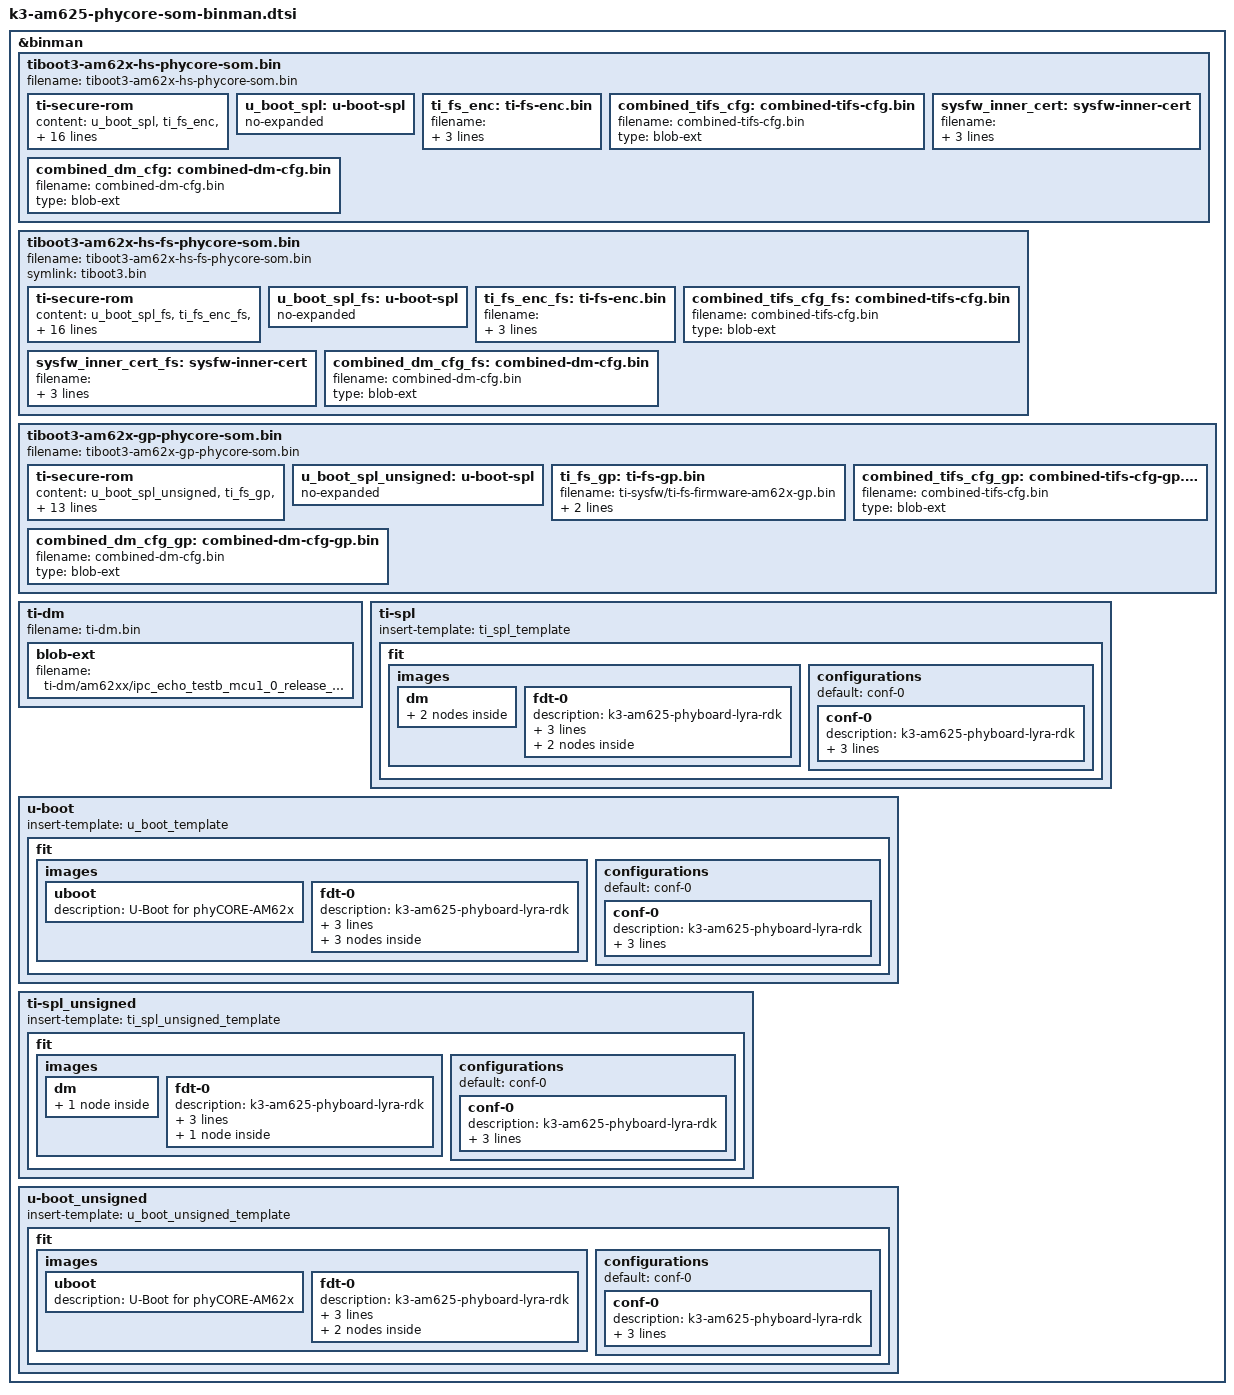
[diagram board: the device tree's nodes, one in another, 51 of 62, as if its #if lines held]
// SPDX-License-Identifier: GPL-2.0
/*
 * Based on k3-am625-sk-binman.dtsi
 *
 * Copyright (C) 2022 - 2023 PHYTEC Messtechnik GmbH
 * Author: Wadim Egorov <w.egorov@phytec.de>
 */

#include "k3-binman.dtsi"

#ifdef CONFIG_TARGET_PHYCORE_AM62X_R5
&binman {
	tiboot3-am62x-hs-phycore-som.bin {
		filename = "tiboot3-am62x-hs-phycore-som.bin";
		ti-secure-rom {
			content = <&u_boot_spl>, <&ti_fs_enc>, <&combined_tifs_cfg>,
				<&combined_dm_cfg>, <&sysfw_inner_cert>;
			combined;
			dm-data;
			sysfw-inner-cert;
			keyfile = "custMpk.pem";
			sw-rev = <1>;
			content-sbl = <&u_boot_spl>;
			content-sysfw = <&ti_fs_enc>;
			content-sysfw-data = <&combined_tifs_cfg>;
			content-sysfw-inner-cert = <&sysfw_inner_cert>;
			content-dm-data = <&combined_dm_cfg>;
			load = <0x43c00000>;
			load-sysfw = <0x40000>;
			load-sysfw-data = <0x67000>;
			load-dm-data = <0x43c3a800>;
		};
		u_boot_spl: u-boot-spl {
			no-expanded;
		};
		ti_fs_enc: ti-fs-enc.bin {
			filename = "ti-sysfw/ti-fs-firmware-am62x-hs-enc.bin";
			type = "blob-ext";
			optional;
		};
		combined_tifs_cfg: combined-tifs-cfg.bin {
			filename = "combined-tifs-cfg.bin";
			type = "blob-ext";
		};
		sysfw_inner_cert: sysfw-inner-cert {
			filename = "ti-sysfw/ti-fs-firmware-am62x-hs-cert.bin";
			type = "blob-ext";
			optional;
		};
		combined_dm_cfg: combined-dm-cfg.bin {
			filename = "combined-dm-cfg.bin";
			type = "blob-ext";
		};
	};
};

&binman {
	tiboot3-am62x-hs-fs-phycore-som.bin {
		filename = "tiboot3-am62x-hs-fs-phycore-som.bin";
		symlink = "tiboot3.bin";
		ti-secure-rom {
			content = <&u_boot_spl_fs>, <&ti_fs_enc_fs>, <&combined_tifs_cfg_fs>,
				<&combined_dm_cfg_fs>, <&sysfw_inner_cert_fs>;
			combined;
			dm-data;
			sysfw-inner-cert;
			keyfile = "custMpk.pem";
			sw-rev = <1>;
			content-sbl = <&u_boot_spl_fs>;
			content-sysfw = <&ti_fs_enc_fs>;
			content-sysfw-data = <&combined_tifs_cfg_fs>;
			content-sysfw-inner-cert = <&sysfw_inner_cert_fs>;
			content-dm-data = <&combined_dm_cfg_fs>;
			load = <0x43c00000>;
			load-sysfw = <0x40000>;
			load-sysfw-data = <0x67000>;
			load-dm-data = <0x43c3a800>;
		};
		u_boot_spl_fs: u-boot-spl {
			no-expanded;
		};
		ti_fs_enc_fs: ti-fs-enc.bin {
			filename = "ti-sysfw/ti-fs-firmware-am62x-hs-fs-enc.bin";
			type = "blob-ext";
			optional;
		};
		combined_tifs_cfg_fs: combined-tifs-cfg.bin {
			filename = "combined-tifs-cfg.bin";
			type = "blob-ext";
		};
		sysfw_inner_cert_fs: sysfw-inner-cert {
			filename = "ti-sysfw/ti-fs-firmware-am62x-hs-fs-cert.bin";
			type = "blob-ext";
			optional;
		};
		combined_dm_cfg_fs: combined-dm-cfg.bin {
			filename = "combined-dm-cfg.bin";
			type = "blob-ext";
		};
	};
};

&binman {
	tiboot3-am62x-gp-phycore-som.bin {
		filename = "tiboot3-am62x-gp-phycore-som.bin";
		ti-secure-rom {
			content = <&u_boot_spl_unsigned>, <&ti_fs_gp>,
				<&combined_tifs_cfg_gp>, <&combined_dm_cfg_gp>;
			combined;
			dm-data;
			content-sbl = <&u_boot_spl_unsigned>;
			load = <0x43c00000>;
			content-sysfw = <&ti_fs_gp>;
			load-sysfw = <0x40000>;
			content-sysfw-data = <&combined_tifs_cfg_gp>;
			load-sysfw-data = <0x67000>;
			content-dm-data = <&combined_dm_cfg_gp>;
			load-dm-data = <0x43c3a800>;
			sw-rev = <1>;
			keyfile = "ti-degenerate-key.pem";
		};
		u_boot_spl_unsigned: u-boot-spl {
			no-expanded;
		};
		ti_fs_gp: ti-fs-gp.bin {
			filename = "ti-sysfw/ti-fs-firmware-am62x-gp.bin";
			type = "blob-ext";
			optional;
		};
		combined_tifs_cfg_gp: combined-tifs-cfg-gp.bin {
			filename = "combined-tifs-cfg.bin";
			type = "blob-ext";
		};
		combined_dm_cfg_gp: combined-dm-cfg-gp.bin {
			filename = "combined-dm-cfg.bin";
			type = "blob-ext";
		};
	};
};
#endif /* CONFIG_TARGET_PHYCORE_AM62X_R5 */

#ifdef CONFIG_TARGET_PHYCORE_AM62X_A53
#define SPL_AM625_PHYBOARD_LYRA_DTB "spl/dts/k3-am625-phyboard-lyra-rdk.dtb"
#define AM625_PHYBOARD_LYRA_DTB "u-boot.dtb"

&binman {
	ti-dm {
		filename = "ti-dm.bin";
		blob-ext {
			filename = "ti-dm/am62xx/ipc_echo_testb_mcu1_0_release_strip.xer5f";
		};
	};
	ti-spl {
		insert-template = <&ti_spl_template>;

		fit {

			images {
				dm {
					ti-secure {
						content = <&dm>;
						keyfile = "custMpk.pem";
					};
					dm: blob-ext {
						filename = "ti-dm.bin";
					};
				};

				fdt-0 {
					description = "k3-am625-phyboard-lyra-rdk";
					type = "flat_dt";
					arch = "arm";
					compression = "none";
					ti-secure {
						content = <&spl_am625_phyboard_lyra_dtb>;
						keyfile = "custMpk.pem";
					};
					spl_am625_phyboard_lyra_dtb: blob-ext {
						filename = SPL_AM625_PHYBOARD_LYRA_DTB;
					};
				};
			};

			configurations {
				default = "conf-0";

				conf-0 {
					description = "k3-am625-phyboard-lyra-rdk";
					firmware = "atf";
					loadables = "tee", "dm", "spl";
					fdt = "fdt-0";
				};
			};
		};
	};
};

&binman {
	u-boot {
		insert-template = <&u_boot_template>;

		fit {
			images {
				uboot {
					description = "U-Boot for phyCORE-AM62x";
				};

				fdt-0 {
					description = "k3-am625-phyboard-lyra-rdk";
					type = "flat_dt";
					arch = "arm";
					compression = "none";
					ti-secure {
						content = <&am625_phyboard_lyra_dtb>;
						keyfile = "custMpk.pem";
					};
					am625_phyboard_lyra_dtb: blob-ext {
						filename = AM625_PHYBOARD_LYRA_DTB;
					};
					hash {
						algo = "crc32";
					};
				};
			};

			configurations {
				default = "conf-0";

				conf-0 {
					description = "k3-am625-phyboard-lyra-rdk";
					firmware = "uboot";
					loadables = "uboot";
					fdt = "fdt-0";
				};
			};
		};
	};
};

&binman {
	ti-spl_unsigned {
		insert-template = <&ti_spl_unsigned_template>;

		fit {
			images {
				dm {
					blob-ext {
						filename = "ti-dm.bin";
					};
				};

				fdt-0 {
					description = "k3-am625-phyboard-lyra-rdk";
					type = "flat_dt";
					arch = "arm";
					compression = "none";
					spl_am625_phyboard_lyra_dtb_unsigned: blob {
						filename = SPL_AM625_PHYBOARD_LYRA_DTB;
					};
				};
			};

			configurations {
				default = "conf-0";

				conf-0 {
					description = "k3-am625-phyboard-lyra-rdk";
					firmware = "atf";
					loadables = "tee", "dm", "spl";
					fdt = "fdt-0";
				};
			};
		};
	};
};

&binman {
	u-boot_unsigned {
		insert-template = <&u_boot_unsigned_template>;

		fit {
			images {
				uboot {
					description = "U-Boot for phyCORE-AM62x";
				};

				fdt-0 {
					description = "k3-am625-phyboard-lyra-rdk";
					type = "flat_dt";
					arch = "arm";
					compression = "none";
					am625_phyboard_lyra_dtb_unsigned: blob {
						filename = AM625_PHYBOARD_LYRA_DTB;
					};
					hash {
						algo = "crc32";
					};
				};
			};

			configurations {
				default = "conf-0";

				conf-0 {
					description = "k3-am625-phyboard-lyra-rdk";
					firmware = "uboot";
					loadables = "uboot";
					fdt = "fdt-0";
				};
			};
		};
	};
};
#endif /* CONFIG_TARGET_PHYCORE_AM62X_A53 */
